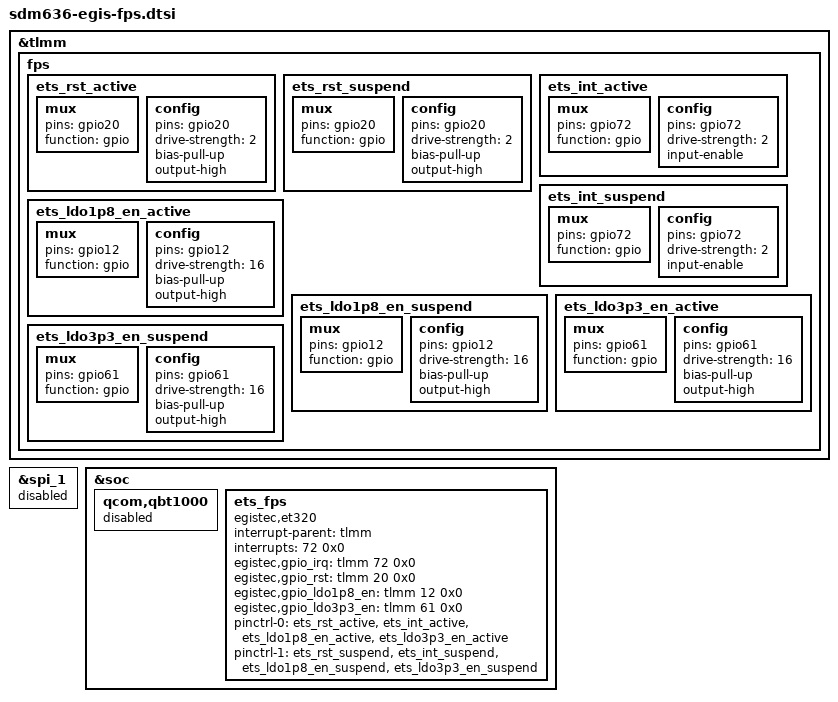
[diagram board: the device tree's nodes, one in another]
/* Copyright (c) 2017, Motorola Mobility Inc. All rights reserved.
 *
 * This program is free software; you can redistribute it and/or modify
 * it under the terms of the GNU General Public License version 2 and
 * only version 2 as published by the Free Software Foundation.
 *
 * This program is distributed in the hope that it will be useful,
 * but WITHOUT ANY WARRANTY; without even the implied warranty of
 * MERCHANTABILITY or FITNESS FOR A PARTICULAR PURPOSE.  See the
 * GNU General Public License for more details.
 */

&tlmm {

	/delete-node/ eb_chrg_conf;
	/delete-node/ fps;

	fps: fps {
		ets_rst_active: ets_rst_active {
			/* RESET */
			mux {
				pins = "gpio20";
				function = "gpio";
			};

			config {
				pins = "gpio20";
				drive-strength = <2>; /* 2 MA */
				bias-pull-up; /* pull up */
				output-high;
			};
		};

		ets_rst_suspend: ets_rst_suspend{
			/* RESET */
			mux {
				pins = "gpio20";
				function = "gpio";
			};

			config {
				pins = "gpio20";
				drive-strength = <2>; /* 2 MA */
				bias-pull-up; /* pull up */
				output-high;
			};
		};

		ets_int_active: ets_int_active {
			/* INTERRUPT */
			mux {
				pins = "gpio72";
				function = "gpio";
			};

			config {
				pins = "gpio72";
				drive-strength = <2>; /* 2 MA */
				input-enable;
			};
		};

		ets_int_suspend: ets_int_suspend{
			/* INTERRUPT */
			mux {
				pins = "gpio72";
				function = "gpio";
			};

			config {
				pins = "gpio72";
				drive-strength = <2>; /* 2 MA */
				input-enable;
			};
		};

		ets_ldo1p8_en_active: ets_ldo1p8_en_active {
			/* LDO_EN */
			mux {
				pins = "gpio12";
				function = "gpio";
			};

			config {
				pins = "gpio12";
				drive-strength = <16>;
				bias-pull-up; /* pull up */
				output-high;
			};
		};

		ets_ldo1p8_en_suspend: ets_ldo1p8_en_suspend{
			/* LDO_EN */
			mux {
				pins = "gpio12";
				function = "gpio";
			};

			config {
				pins = "gpio12";
				drive-strength = <16>;
				bias-pull-up; /* pull up */
				output-high;
			};
		};

		ets_ldo3p3_en_active: ets_ldo3p3_en_active {
			/* LDO3_EN */
			mux {
				pins = "gpio61";
				function = "gpio";
			};

			config {
				pins = "gpio61";
				drive-strength = <16>;
				bias-pull-up; /* pull up */
				output-high;
			};
		};

		ets_ldo3p3_en_suspend: ets_ldo3p3_en_suspend{
			/* LDO3_EN */
			mux {
				pins = "gpio61";
				function = "gpio";
			};

			config {
				pins = "gpio61";
				drive-strength = <16>;
				bias-pull-up; /* pull up */
				output-high;
			};
		};
	};
};

&spi_1 {
	status = "disabled";
	/delete-node/ fpc_fpc1020@0;
};

&soc {
	qcom,qbt1000{
		status = "disabled";
	};

	ets_fps: ets_fps{
		compatible = "egistec,et320", "egistec,et516";
		status = "ok";
		//reg = <0>;
		interrupt-parent = <&tlmm>;
		interrupts = <72 0x0>;
		egistec,gpio_irq    = <&tlmm 72 0x0>;
		egistec,gpio_rst    = <&tlmm 20 0x0>;
		egistec,gpio_ldo1p8_en = <&tlmm 12 0x0>;
		egistec,gpio_ldo3p3_en = <&tlmm 61 0x0>;
		pinctrl-names = "default", "suspend";
		pinctrl-0 = <&ets_rst_active &ets_int_active &ets_ldo1p8_en_active &ets_ldo3p3_en_active>;
		pinctrl-1 = <&ets_rst_suspend &ets_int_suspend &ets_ldo1p8_en_suspend &ets_ldo3p3_en_suspend>;
		//ets-vcc-3p3 = <&pm660l_l8>;
		//ets-vdd-1p8 = <&pm660_l11>;
	};
};


